# STM32L052C6T6 register map
File version: 1.0
Registers are 32-bit, access not given, reset 0x0 unless marked. A register's access mark holds for its fields unless they carry their own. Offsets are from the block's base; [hi:lo] are bit positions; {n}, {i} and the like mark numbered series; 'fields as' and 'values as' point back to an identical list.

## EXTI
Base 0x40010400
0x00 IMR
  [29:0] IM
0x04 EMR
  [29:0] EM
0x08 RTSR
  [22:0] RT
0x0C FTSR
  [22:0] FT
0x10 SWIER
  [22:0] SWI
0x14 PR
  [22:0] PIF

## TIM21
Base 0x40010800
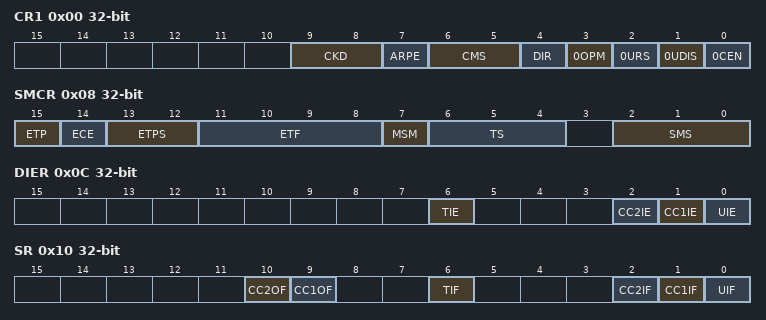
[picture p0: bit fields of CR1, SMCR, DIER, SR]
0x00 CR1
  [9:8] CKD, [7] ARPE, [6:5] CMS, [4] DIR, [3] 0OPM, [2] 0URS, [1] 0UDIS, [0] 0CEN
0x04 CR2
  [6:4] MMS
0x08 SMCR
  [15] ETP, [14] ECE, [13:12] ETPS, [11:8] ETF, [7] MSM, [6:4] TS, [2:0] SMS
0x0C DIER
  [6] TIE, [2] CC2IE, [1] CC1IE, [0] UIE
0x10 SR
  [10] CC2OF, [9] CC1OF, [6] TIF, [2] CC2IF, [1] CC1IF, [0] UIF
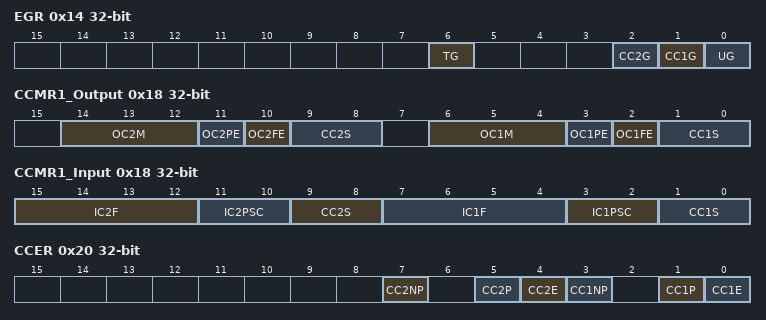
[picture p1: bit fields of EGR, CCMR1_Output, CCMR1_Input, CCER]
0x14 EGR
  [6] TG, [2] CC2G, [1] CC1G, [0] UG
0x18 CCMR1_Output
  [14:12] OC2M, [11] OC2PE, [10] OC2FE, [9:8] CC2S, [6:4] OC1M, [3] OC1PE, [2] OC1FE, [1:0] CC1S
0x18 CCMR1_Input
  [15:12] IC2F, [11:10] IC2PSC, [9:8] CC2S, [7:4] IC1F, [3:2] IC1PSC, [1:0] CC1S
0x20 CCER
  [7] CC2NP, [5] CC2P, [4] CC2E, [3] CC1NP, [1] CC1P, [0] CC1E
0x24 CNT
  [15:0] CNT
0x28 PSC
  [15:0] PSC
0x2C ARR
  [15:0] ARR
0x34 CCR1
  [15:0] CCR1
0x38 CCR2
  [15:0] CCR2
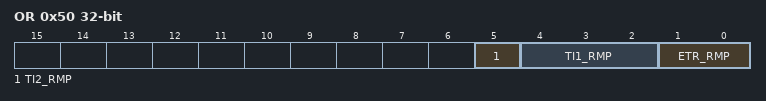
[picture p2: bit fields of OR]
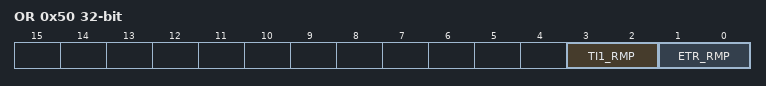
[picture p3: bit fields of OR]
0x50 OR
  [5] TI2_RMP, [4:2] TI1_RMP, [1:0] ETR_RMP

## TIM22
Base 0x40011400
Registers as TIM21; these are added or differ:
0x50 OR
  [3:2] TI1_RMP, [1:0] ETR_RMP

## FW
Base 0x40011C00
0x00 CSSA
  [23:8] ADD
0x04 CSL
  [21:8] LENG
0x08 NVDSSA
  [23:8] ADD
0x0C NVDSL
  [21:8] LENG
0x10 VDSSA
  [15:6] ADD
0x14 VDSL
  [15:6] LENG
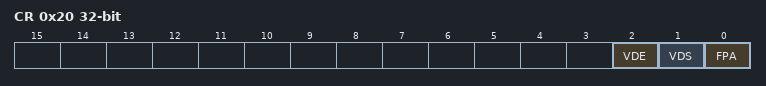
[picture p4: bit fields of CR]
0x20 CR
  [2] VDE, [1] VDS, [0] FPA

## ADC1
Base 0x40012400
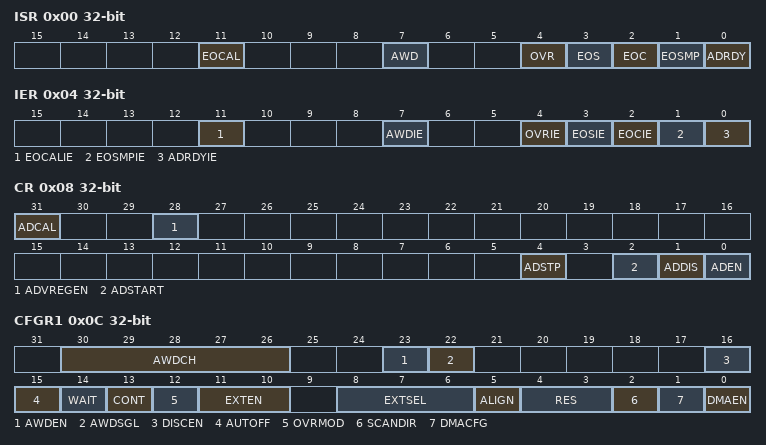
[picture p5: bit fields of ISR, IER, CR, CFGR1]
0x00 ISR
  [11] EOCAL, [7] AWD, [4] OVR, [3] EOS, [2] EOC, [1] EOSMP, [0] ADRDY
0x04 IER
  [11] EOCALIE, [7] AWDIE, [4] OVRIE, [3] EOSIE, [2] EOCIE, [1] EOSMPIE, [0] ADRDYIE
0x08 CR
  [31] ADCAL, [28] ADVREGEN, [4] ADSTP, [2] ADSTART, [1] ADDIS, [0] ADEN
0x0C CFGR1
  [30:26] AWDCH, [23] AWDEN, [22] AWDSGL, [16] DISCEN, [15] AUTOFF, [14] WAIT, [13] CONT, [12] OVRMOD, [11:10] EXTEN, [8:6] EXTSEL, [5] ALIGN, [4:3] RES, [2] SCANDIR, [1] DMACFG, [0] DMAEN
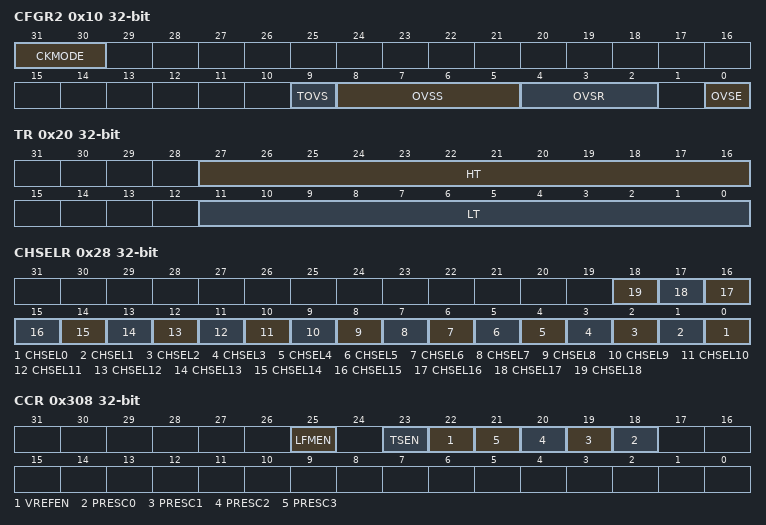
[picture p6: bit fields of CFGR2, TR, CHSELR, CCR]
0x10 CFGR2
  [31:30] CKMODE, [9] TOVS, [8:5] OVSS, [4:2] OVSR, [0] OVSE
0x14 SMPR
  [2:0] SMP
0x20 TR
  [27:16] HT, [11:0] LT
0x28 CHSELR
  [n] CHSEL{n} (n=0..18)
0x40 DR
  [15:0] DATA
0xB4 CALFACT
  [6:0] CALFACT
0x308 CCR
  [25] LFMEN, [23] TSEN, [22] VREFEN, [n+18] PRESC{n} (n=0..3)

## DBG
Base 0x40015800
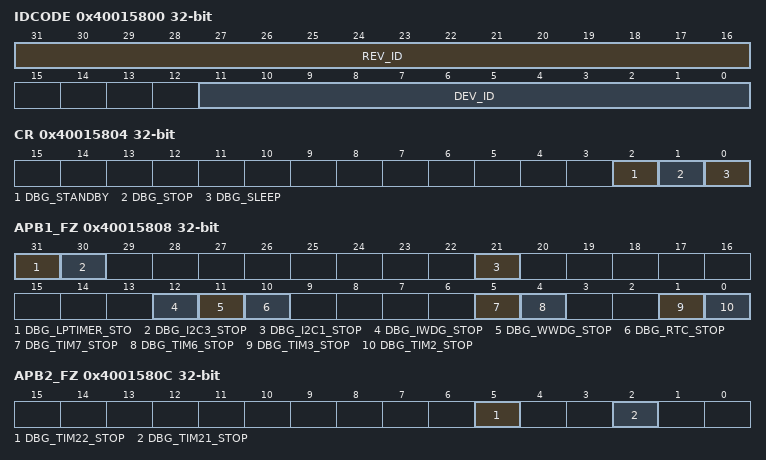
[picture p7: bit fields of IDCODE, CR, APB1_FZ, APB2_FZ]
0x40015800 IDCODE
  [31:16] REV_ID, [11:0] DEV_ID
0x40015804 CR
  [2] DBG_STANDBY, [1] DBG_STOP, [0] DBG_SLEEP
0x40015808 APB1_FZ
  [31] DBG_LPTIMER_STO, [30] DBG_I2C3_STOP, [21] DBG_I2C1_STOP, [12] DBG_IWDG_STOP, [11] DBG_WWDG_STOP, [10] DBG_RTC_STOP, [5] DBG_TIM7_STOP, [4] DBG_TIM6_STOP, [1] DBG_TIM3_STOP, [0] DBG_TIM2_STOP
0x4001580C APB2_FZ
  [5] DBG_TIM22_STOP, [2] DBG_TIM21_STOP

## DMA1
Base 0x40020000
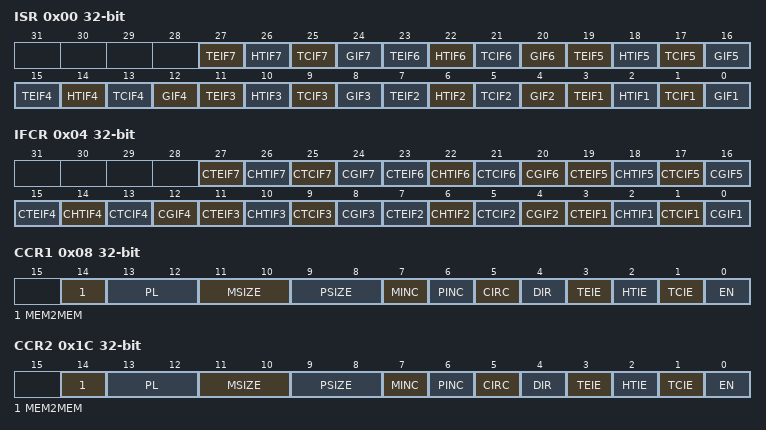
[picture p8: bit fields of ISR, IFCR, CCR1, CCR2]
0x00 ISR
  [4n-1] TEIF{n} (n=1..7), [4n-2] HTIF{n} (n=1..7), [4n-3] TCIF{n} (n=1..7), [4n-4] GIF{n} (n=1..7)
0x04 IFCR
  [4n-1] CTEIF{n} (n=1..7), [4n-2] CHTIF{n} (n=1..7), [4n-3] CTCIF{n} (n=1..7), [4n-4] CGIF{n} (n=1..7)
0x08 CCR1
  [14] MEM2MEM, [13:12] PL, [11:10] MSIZE, [9:8] PSIZE, [7] MINC, [6] PINC, [5] CIRC, [4] DIR, [3] TEIE, [2] HTIE, [1] TCIE, [0] EN
0x0C CNDTR1
  [15:0] NDTR
0x10 CPAR1
  [31:0] PA
{0x0+0x14*i} CMAR{i} (i=1..7)
  [31:0] MA
0x1C CCR2
  fields as CCR1
0x20 CNDTR2
  [15:0] NDTR
0x24 CPAR2
  [31:0] PA
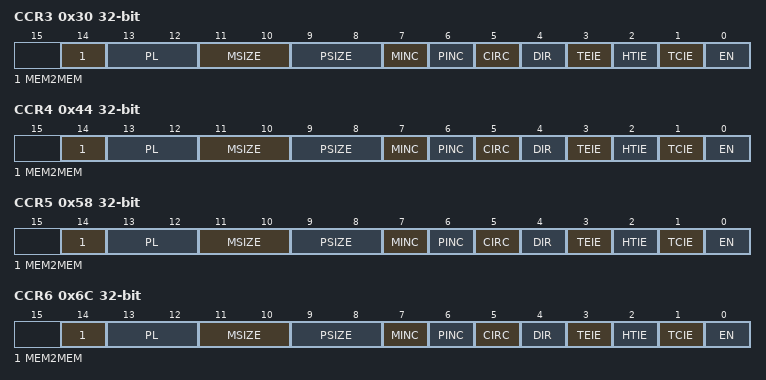
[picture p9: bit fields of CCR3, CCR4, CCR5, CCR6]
0x30 CCR3
  fields as CCR1
0x34 CNDTR3
  [15:0] NDTR
0x38 CPAR3
  [31:0] PA
0x44 CCR4
  fields as CCR1
0x48 CNDTR4
  [15:0] NDTR
0x4C CPAR4
  [31:0] PA
0x58 CCR5
  fields as CCR1
0x5C CNDTR5
  [15:0] NDTR
0x60 CPAR5
  [31:0] PA
0x6C CCR6
  fields as CCR1
0x70 CNDTR6
  [15:0] NDTR
0x74 CPAR6
  [31:0] PA
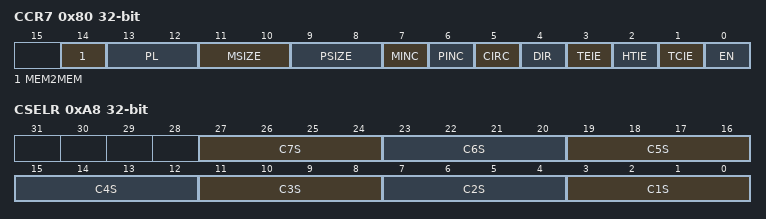
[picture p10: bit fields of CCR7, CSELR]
0x80 CCR7
  fields as CCR1
0x84 CNDTR7
  [15:0] NDTR
0x88 CPAR7
  [31:0] PA
0xA8 CSELR
  [4n-1:4n-4] C{n}S (n=1..7)

## RCC
Base 0x40021000
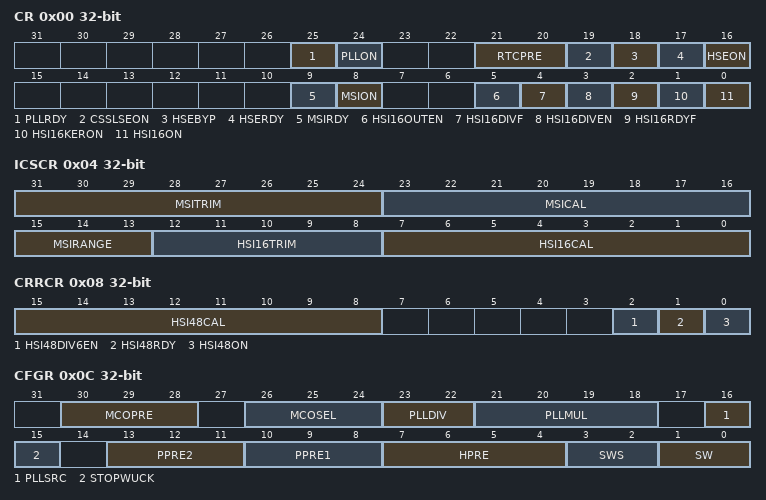
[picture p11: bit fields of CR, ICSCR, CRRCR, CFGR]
0x00 CR
  [25] PLLRDY, [24] PLLON, [21:20] RTCPRE, [19] CSSLSEON, [18] HSEBYP, [17] HSERDY, [16] HSEON, [9] MSIRDY, [8] MSION, [5] HSI16OUTEN, [4] HSI16DIVF, [3] HSI16DIVEN, [2] HSI16RDYF, [1] HSI16KERON, [0] HSI16ON
0x04 ICSCR
  [31:24] MSITRIM, [23:16] MSICAL, [15:13] MSIRANGE, [12:8] HSI16TRIM, [7:0] HSI16CAL
0x08 CRRCR
  [15:8] HSI48CAL, [2] HSI48DIV6EN, [1] HSI48RDY, [0] HSI48ON
0x0C CFGR
  [30:28] MCOPRE, [26:24] MCOSEL, [23:22] PLLDIV, [21:18] PLLMUL, [16] PLLSRC, [15] STOPWUCK, [13:11] PPRE2, [10:8] PPRE1, [7:4] HPRE, [3:2] SWS, [1:0] SW
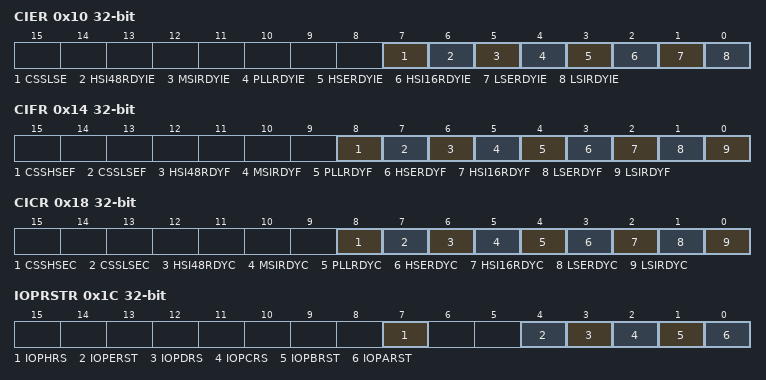
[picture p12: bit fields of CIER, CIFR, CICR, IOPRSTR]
0x10 CIER
  [7] CSSLSE, [6] HSI48RDYIE, [5] MSIRDYIE, [4] PLLRDYIE, [3] HSERDYIE, [2] HSI16RDYIE, [1] LSERDYIE, [0] LSIRDYIE
0x14 CIFR
  [8] CSSHSEF, [7] CSSLSEF, [6] HSI48RDYF, [5] MSIRDYF, [4] PLLRDYF, [3] HSERDYF, [2] HSI16RDYF, [1] LSERDYF, [0] LSIRDYF
0x18 CICR
  [8] CSSHSEC, [7] CSSLSEC, [6] HSI48RDYC, [5] MSIRDYC, [4] PLLRDYC, [3] HSERDYC, [2] HSI16RDYC, [1] LSERDYC, [0] LSIRDYC
0x1C IOPRSTR
  [7] IOPHRS, [4] IOPERST, [3] IOPDRS, [2] IOPCRS, [1] IOPBRST, [0] IOPARST
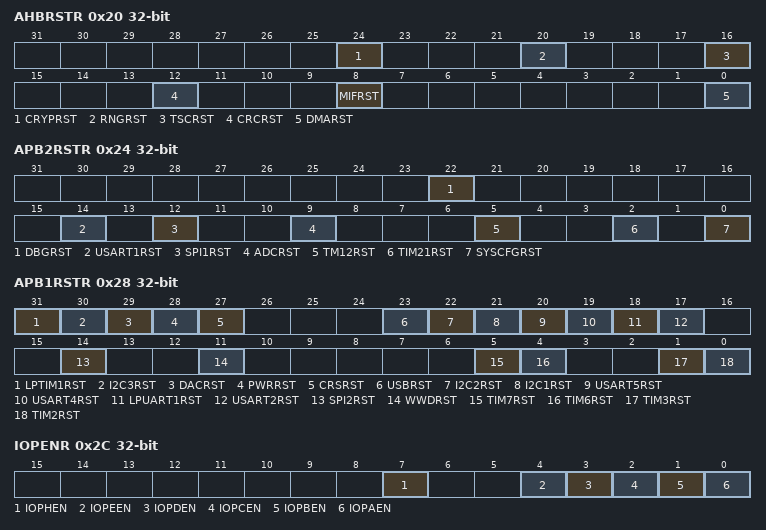
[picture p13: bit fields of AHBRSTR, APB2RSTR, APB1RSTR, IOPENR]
0x20 AHBRSTR
  [24] CRYPRST, [20] RNGRST, [16] TSCRST, [12] CRCRST, [8] MIFRST, [0] DMARST
0x24 APB2RSTR
  [22] DBGRST, [14] USART1RST, [12] SPI1RST, [9] ADCRST, [5] TM12RST, [2] TIM21RST, [0] SYSCFGRST
0x28 APB1RSTR
  [31] LPTIM1RST, [30] I2C3RST, [29] DACRST, [28] PWRRST, [27] CRSRST, [23] USBRST, [22] I2C2RST, [21] I2C1RST, [20] USART5RST, [19] USART4RST, [18] LPUART1RST, [17] USART2RST, [14] SPI2RST, [11] WWDRST, [5] TIM7RST, [4] TIM6RST, [1] TIM3RST, [0] TIM2RST
0x2C IOPENR
  [7] IOPHEN, [4] IOPEEN, [3] IOPDEN, [2] IOPCEN, [1] IOPBEN, [0] IOPAEN
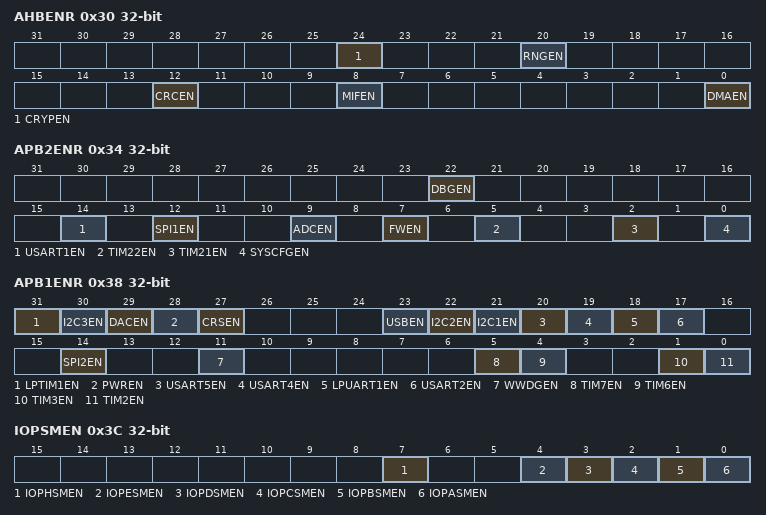
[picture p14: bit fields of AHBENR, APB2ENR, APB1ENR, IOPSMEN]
0x30 AHBENR
  [24] CRYPEN, [20] RNGEN, [12] CRCEN, [8] MIFEN, [0] DMAEN
0x34 APB2ENR
  [22] DBGEN, [14] USART1EN, [12] SPI1EN, [9] ADCEN, [7] FWEN, [5] TIM22EN, [2] TIM21EN, [0] SYSCFGEN
0x38 APB1ENR
  [31] LPTIM1EN, [30] I2C3EN, [29] DACEN, [28] PWREN, [27] CRSEN, [23] USBEN, [22] I2C2EN, [21] I2C1EN, [20] USART5EN, [19] USART4EN, [18] LPUART1EN, [17] USART2EN, [14] SPI2EN, [11] WWDGEN, [5] TIM7EN, [4] TIM6EN, [1] TIM3EN, [0] TIM2EN
0x3C IOPSMEN
  [7] IOPHSMEN, [4] IOPESMEN, [3] IOPDSMEN, [2] IOPCSMEN, [1] IOPBSMEN, [0] IOPASMEN
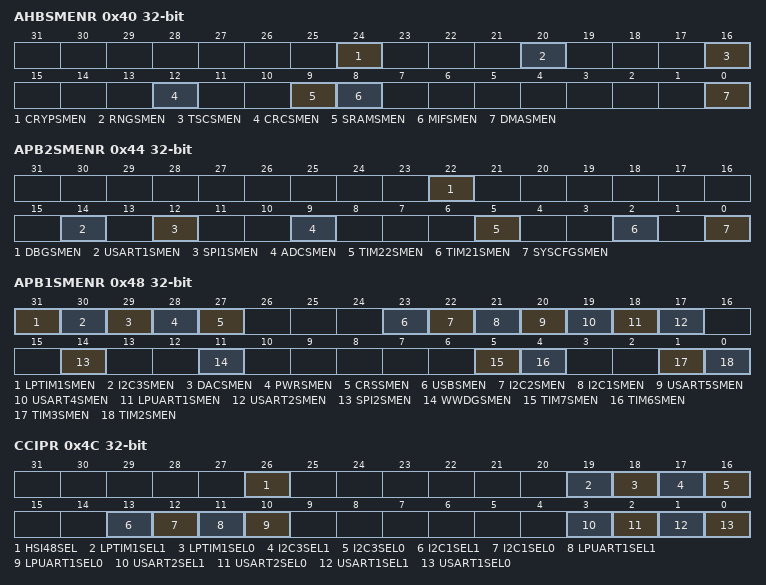
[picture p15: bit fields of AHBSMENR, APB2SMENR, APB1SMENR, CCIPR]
0x40 AHBSMENR
  [24] CRYPSMEN, [20] RNGSMEN, [16] TSCSMEN, [12] CRCSMEN, [9] SRAMSMEN, [8] MIFSMEN, [0] DMASMEN
0x44 APB2SMENR
  [22] DBGSMEN, [14] USART1SMEN, [12] SPI1SMEN, [9] ADCSMEN, [5] TIM22SMEN, [2] TIM21SMEN, [0] SYSCFGSMEN
0x48 APB1SMENR
  [31] LPTIM1SMEN, [30] I2C3SMEN, [29] DACSMEN, [28] PWRSMEN, [27] CRSSMEN, [23] USBSMEN, [22] I2C2SMEN, [21] I2C1SMEN, [20] USART5SMEN, [19] USART4SMEN, [18] LPUART1SMEN, [17] USART2SMEN, [14] SPI2SMEN, [11] WWDGSMEN, [5] TIM7SMEN, [4] TIM6SMEN, [1] TIM3SMEN, [0] TIM2SMEN
0x4C CCIPR
  [26] HSI48SEL, [19] LPTIM1SEL1, [18] LPTIM1SEL0, [17] I2C3SEL1, [16] I2C3SEL0, [13] I2C1SEL1, [12] I2C1SEL0, [11] LPUART1SEL1, [10] LPUART1SEL0, [3] USART2SEL1, [2] USART2SEL0, [1] USART1SEL1, [0] USART1SEL0
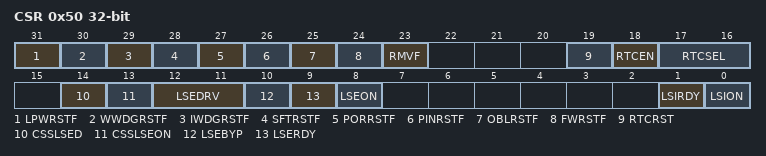
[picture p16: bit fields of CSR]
0x50 CSR
  [31] LPWRSTF, [30] WWDGRSTF, [29] IWDGRSTF, [28] SFTRSTF, [27] PORRSTF, [26] PINRSTF, [25] OBLRSTF, [24] FWRSTF, [23] RMVF, [19] RTCRST, [18] RTCEN, [17:16] RTCSEL, [14] CSSLSED, [13] CSSLSEON, [12:11] LSEDRV, [10] LSEBYP, [9] LSERDY, [8] LSEON, [1] LSIRDY, [0] LSION

## FLASH
Base 0x40022000
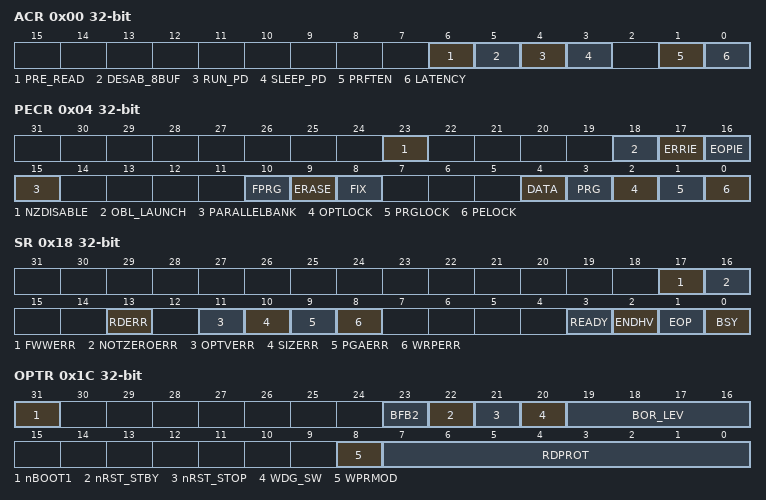
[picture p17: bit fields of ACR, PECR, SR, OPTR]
0x00 ACR
  [6] PRE_READ, [5] DESAB_8BUF, [4] RUN_PD, [3] SLEEP_PD, [1] PRFTEN, [0] LATENCY
0x04 PECR
  [23] NZDISABLE, [18] OBL_LAUNCH, [17] ERRIE, [16] EOPIE, [15] PARALLELBANK, [10] FPRG, [9] ERASE, [8] FIX, [4] DATA, [3] PRG, [2] OPTLOCK, [1] PRGLOCK, [0] PELOCK
0x08 PDKEYR
0x0C PKEYR
0x10 PRGKEYR
0x14 OPTKEYR
0x18 SR
  [17] FWWERR, [16] NOTZEROERR, [13] RDERR, [11] OPTVERR, [10] SIZERR, [9] PGAERR, [8] WRPERR, [3] READY, [2] ENDHV, [1] EOP, [0] BSY
0x1C OPTR
  [31] nBOOT1, [23] BFB2, [22] nRST_STBY, [21] nRST_STOP, [20] WDG_SW, [19:16] BOR_LEV, [8] WPRMOD, [7:0] RDPROT
0x20 WRPROT1
0x80 WRPROT2
  [15:0] WRPROT2

## CRC
Base 0x40023000
0x00 DR
0x04 IDR
  [7:0] IDR
0x08 CR
  [7] REV_OUT, [6:5] REV_IN, [4:3] POLYSIZE, [0] RESET
0x10 INIT
  [31:0] CRC_INIT
0x14 POL

## TSC
Base 0x40024000
0x00 CR
  [31:28] CTPH, [27:24] CTPL, [23:17] SSD, [16] SSE, [15] SSPSC, [14:12] PGPSC, [7:5] MCV, [4] IODEF, [3] SYNCPOL, [2] AM, [1] START, [0] TSCE
0x04 IER
  [1] MCEIE, [0] EOAIE
0x08 ICR
  [1] MCEIC, [0] EOAIC
0x0C ISR
  [1] MCEF, [0] EOAF
0x10 IOHCR
  [4n-1] G{n}_IO4 (n=1..8), [4n-2] G{n}_IO3 (n=1..8), [4n-3] G{n}_IO2 (n=1..8), [4n-4] G{n}_IO1 (n=1..8)
0x18 IOASCR
  fields as IOHCR
0x20 IOSCR
  fields as IOHCR
0x28 IOCCR
  fields as IOHCR
0x30 IOGCSR
  [n+15] G{n}S (n=1..8), [n-1] G{n}E (n=1..8)
{0x30+4i} IOG{i}CR (i=1..8)
  [13:0] CNT

## RNG
Base 0x40025000
0x00 CR
  [5] CED, [3] IE, [2] RNGEN
0x04 SR
  [6] SEIS, [5] CEIS, [2] SECS, [1] CECS, [0] DRDY
0x08 DR
  [31:0] RNDATA

## AES
Base 0x40026000
0x00 CR
  [12] DMAOUTEN, [11] DMAINEN, [10] ERRIE, [9] CCFIE, [8] ERRC, [7] CCFC, [6:5] CHMOD, [4:3] MODE, [2:1] DATATYPE, [0] EN
0x04 SR
  [2] WRERR, [1] RDERR, [0] CCF
0x08 DINR
  [31:0] DIN
0x0C DOUTR
  [31:0] DOUT
{0x10+4i} KEYR{i} (i=0..3)
  [31:0] KEY
{0x20+4i} IVR{i} (i=0..3)
  [31:0] IVI

## GPIOA
Base 0x50000000
0x00 MODER
  [2n+1:2n] MODE{n} (n=0..15)
0x04 OTYPER
  [n] OT{n} (n=0..15)
0x08 OSPEEDR
  [2n+1:2n] OSPEED{n} (n=0..15)
0x0C PUPDR
  [2n+1:2n] PUPD{n} (n=0..15)
0x10 IDR
  [n] ID{n} (n=0..15)
0x14 ODR
  [n] OD{n} (n=0..15)
0x18 BSRR
  [n+16] BR{n} (n=0..15), [n] BS{n} (n=0..15)
0x1C LCKR
  [16] LCKK, [n] LCK{n} (n=0..15)
0x20 AFRL
  [4n+3:4n] AFSEL{n} (n=0..7)
0x24 AFRH
  [4n-29:4n-32] AFSEL{n} (n=8..15)
0x28 BRR
  [n] BR{n} (n=0..15)

## GPIOB
Base 0x50000400
Same registers: GPIOC 0x50000800, GPIOD 0x50000C00, GPIOE 0x50001000, GPIOH 0x50001C00
Registers as GPIOA, without PUPDR; these are added or differ:
0x00 MODER
  [2n+1:2n] MODER{n} (n=2..15), [3:2] MODER, [1:0] MODER0
